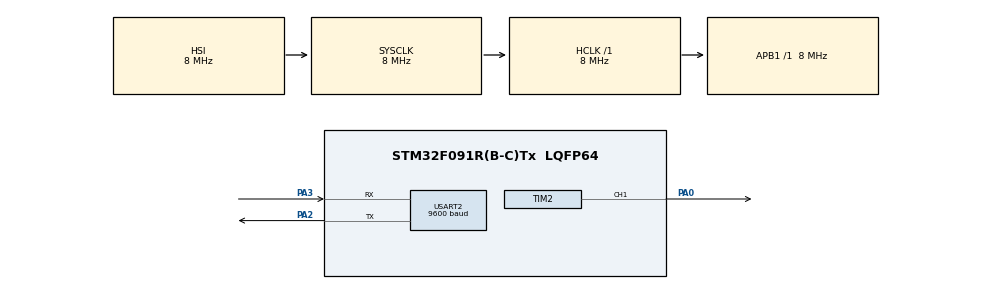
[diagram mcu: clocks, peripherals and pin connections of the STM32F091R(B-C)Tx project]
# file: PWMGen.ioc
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Mcu.Family=STM32F0
Mcu.Name=STM32F091R(B-C)Tx
Mcu.Package=LQFP64
NVIC.USART2_IRQn=true\:0\:0\:false\:false\:true\:true\:true
PA0.Signal=S_TIM2_CH1_ETR
PA2.Mode=Asynchronous
PA2.Signal=USART2_TX
PA3.Mode=Asynchronous
PA3.Signal=USART2_RX
ProjectManager.HeapSize=0x200
ProjectManager.StackSize=0x400
ProjectManager.TargetToolchain=SW4STM32
RCC.AHBFreq_Value=8000000
RCC.APB1Freq_Value=8000000
RCC.APB1TimFreq_Value=8000000
RCC.FLatency-AdvancedSettings=FLASH_LATENCY_0
RCC.HCLKFreq_Value=8000000
RCC.PLLDivider=RCC_PREDIV_DIV2
RCC.PLLMUL=RCC_PLL_MUL12
RCC.PREFETCH_ENABLE-AdvancedSettings=1
RCC.SYSCLKFreq_VALUE=8000000
SH.S_TIM2_CH1_ETR.0=TIM2_CH1,PWM Generation1 CH1
TIM2.Channel-PWM\ Generation1\ CH1=TIM_CHANNEL_1
TIM2.Period=7999
TIM2.Prescaler=1
TIM2.Pulse-PWM\ Generation1\ CH1=3999
USART2.BaudRate=9600
USART2.VirtualMode-Asynchronous=VM_ASYNC
VP_TIM2_VS_ClockSourceINT.Mode=Internal
board=NUCLEO-F091RC

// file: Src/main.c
/* USER CODE BEGIN Header */
/**
  ******************************************************************************
  * @file           : main.c
  * @brief          : Main program body
  ******************************************************************************
  * @attention
  *
  * <h2><center>&copy; Copyright (c) 2020 STMicroelectronics.
  * All rights reserved.</center></h2>
  *
  * This software component is licensed by ST under BSD 3-Clause license,
  * the "License"; You may not use this file except in compliance with the
  * License. You may obtain a copy of the License at:
  *                        opensource.org/licenses/BSD-3-Clause
  *
  ******************************************************************************
  */
/* USER CODE END Header */

#include "main.h"

/* USER CODE BEGIN Includes */
#include <stdlib.h>
/* USER CODE END Includes */

TIM_HandleTypeDef htim2;

UART_HandleTypeDef huart2;

/* USER CODE BEGIN PV */
uint8_t i, fl, data[1], buff[10];
uint16_t counterPeriod, dutyCycle, freq;
char inputf[2] = "f=", inputd[2] = "d=";

/* USER CODE END PV */

void SystemClock_Config(void);
static void MX_GPIO_Init(void);
static void MX_TIM2_Init(void);
static void MX_USART2_UART_Init(void);

/* USER CODE BEGIN 0 */
void cutStr(void);
/* USER CODE END 0 */

int main(void)
{

  /* MCU Configuration--------------------------------------------------------*/

  /* Reset of all peripherals, Initializes the Flash interface and the Systick. */
  HAL_Init();

  /* Configure the system clock */
  SystemClock_Config();

  /* Initialize all configured peripherals */
  MX_GPIO_Init();
  MX_TIM2_Init();
  MX_USART2_UART_Init();
  /* USER CODE BEGIN 2 */
  HAL_TIM_PWM_Start(&htim2, TIM_CHANNEL_1); //iniciar PWM
  HAL_UART_Receive_IT(&huart2,&data,1); //iniciar interrupçao
  /* USER CODE END 2 */

  /* Infinite loop */
  while (1)
  {

    /* USER CODE BEGIN 3 */
	  if (fl==1) //recebeu um enter, fl passou a 1
	  	  {
		  	  if (strncmp(&buff,&inputf,2) == 0)
		  	  {
		  		  cutStr();
		  		  freq = atoi(&buff);
		  		  counterPeriod = 0.5 * (8000000 / freq) - 1;
		  		  TIM2 -> ARR = counterPeriod;
		  	  }
		  	  else if (strncmp(&buff,&inputd,2) == 0)
		  	  {
		  		  cutStr();
		  		  dutyCycle = atoi(&buff);
		  		  TIM2 -> CCR1 = 4*dutyCycle;

		  	  }

		  	  else
		  	  {
		  		  __NOP();
		  	  }

		  	  fl=0;
		  	  i=0;
	  	  }
  }
  /* USER CODE END 3 */
}

void SystemClock_Config(void)
{
  RCC_OscInitTypeDef RCC_OscInitStruct = {0};
  RCC_ClkInitTypeDef RCC_ClkInitStruct = {0};
  RCC_PeriphCLKInitTypeDef PeriphClkInit = {0};

  /** Initializes the CPU, AHB and APB busses clocks
  */
  RCC_OscInitStruct.OscillatorType = RCC_OSCILLATORTYPE_HSI;
  RCC_OscInitStruct.HSIState = RCC_HSI_ON;
  RCC_OscInitStruct.HSICalibrationValue = RCC_HSICALIBRATION_DEFAULT;
  RCC_OscInitStruct.PLL.PLLState = RCC_PLL_NONE;
  if (HAL_RCC_OscConfig(&RCC_OscInitStruct) != HAL_OK)
  {
    Error_Handler();
  }
  /** Initializes the CPU, AHB and APB busses clocks
  */
  RCC_ClkInitStruct.ClockType = RCC_CLOCKTYPE_HCLK|RCC_CLOCKTYPE_SYSCLK
                              |RCC_CLOCKTYPE_PCLK1;
  RCC_ClkInitStruct.SYSCLKSource = RCC_SYSCLKSOURCE_HSI;
  RCC_ClkInitStruct.AHBCLKDivider = RCC_SYSCLK_DIV1;
  RCC_ClkInitStruct.APB1CLKDivider = RCC_HCLK_DIV1;

  if (HAL_RCC_ClockConfig(&RCC_ClkInitStruct, FLASH_LATENCY_0) != HAL_OK)
  {
    Error_Handler();
  }
  PeriphClkInit.PeriphClockSelection = RCC_PERIPHCLK_USART2;
  PeriphClkInit.Usart2ClockSelection = RCC_USART2CLKSOURCE_PCLK1;
  if (HAL_RCCEx_PeriphCLKConfig(&PeriphClkInit) != HAL_OK)
  {
    Error_Handler();
  }
}

static void MX_TIM2_Init(void)
{

  TIM_ClockConfigTypeDef sClockSourceConfig = {0};
  TIM_MasterConfigTypeDef sMasterConfig = {0};
  TIM_OC_InitTypeDef sConfigOC = {0};

  htim2.Instance = TIM2;
  htim2.Init.Prescaler = 1;
  htim2.Init.CounterMode = TIM_COUNTERMODE_UP;
  htim2.Init.Period = 3999;
  htim2.Init.ClockDivision = TIM_CLOCKDIVISION_DIV1;
  htim2.Init.AutoReloadPreload = TIM_AUTORELOAD_PRELOAD_DISABLE;
  if (HAL_TIM_Base_Init(&htim2) != HAL_OK)
  {
    Error_Handler();
  }
  sClockSourceConfig.ClockSource = TIM_CLOCKSOURCE_INTERNAL;
  if (HAL_TIM_ConfigClockSource(&htim2, &sClockSourceConfig) != HAL_OK)
  {
    Error_Handler();
  }
  if (HAL_TIM_PWM_Init(&htim2) != HAL_OK)
  {
    Error_Handler();
  }
  sMasterConfig.MasterOutputTrigger = TIM_TRGO_RESET;
  sMasterConfig.MasterSlaveMode = TIM_MASTERSLAVEMODE_DISABLE;
  if (HAL_TIMEx_MasterConfigSynchronization(&htim2, &sMasterConfig) != HAL_OK)
  {
    Error_Handler();
  }
  sConfigOC.OCMode = TIM_OCMODE_PWM1;
  sConfigOC.Pulse = 1999;
  sConfigOC.OCPolarity = TIM_OCPOLARITY_HIGH;
  sConfigOC.OCFastMode = TIM_OCFAST_DISABLE;
  if (HAL_TIM_PWM_ConfigChannel(&htim2, &sConfigOC, TIM_CHANNEL_1) != HAL_OK)
  {
    Error_Handler();
  }
  HAL_TIM_MspPostInit(&htim2);

}

static void MX_USART2_UART_Init(void)
{

  huart2.Instance = USART2;
  huart2.Init.BaudRate = 9600;
  huart2.Init.WordLength = UART_WORDLENGTH_8B;
  huart2.Init.StopBits = UART_STOPBITS_1;
  huart2.Init.Parity = UART_PARITY_NONE;
  huart2.Init.Mode = UART_MODE_TX_RX;
  huart2.Init.HwFlowCtl = UART_HWCONTROL_NONE;
  huart2.Init.OverSampling = UART_OVERSAMPLING_16;
  huart2.Init.OneBitSampling = UART_ONE_BIT_SAMPLE_DISABLE;
  huart2.AdvancedInit.AdvFeatureInit = UART_ADVFEATURE_NO_INIT;
  if (HAL_UART_Init(&huart2) != HAL_OK)
  {
    Error_Handler();
  }

}

static void MX_GPIO_Init(void)
{

  /* GPIO Ports Clock Enable */
  __HAL_RCC_GPIOA_CLK_ENABLE();

}

/* USER CODE BEGIN 4 */
void HAL_UART_RxCpltCallback(UART_HandleTypeDef *huart)
{

	if(i == 0) //limpar o buffer
	{
		memset(&buff,0,sizeof buff); //preencher buffer com zeros
	}

	if(data[0] != 13) //o caracter não é "enter" (13 em ASCII)
	{
		buff[i] = data[0];
		i++;
	}

	else //data = 13
	{
		fl=1;
	}

	HAL_UART_Receive_IT(&huart2,&data,1); //iniciar interrupçao novamente

}
void cutStr()
{
	int n = 0;
	while(n + 2 < 8)
	{
		buff[n] = buff[n+2];
		n++;
	}
}
/* USER CODE END 4 */

void Error_Handler(void)
{
}

/************************ (C) COPYRIGHT STMicroelectronics *****END OF FILE****/
